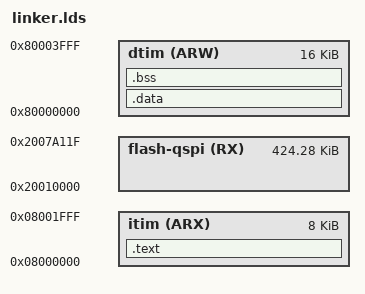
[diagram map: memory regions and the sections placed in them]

ENTRY(_start)

MEMORY
{
        itim       (ARX) : ORIGIN = 0x08000000, LENGTH = 8k
        flash-qspi (RX)  : ORIGIN = 0x20010000, LENGTH = 0x6A120
        dtim       (ARW) : ORIGIN = 0x80000000, LENGTH = 16k
}

SECTIONS
{
        /**********************************************************************
         *                                                                    *
         **********************************************************************/
        .text :
        {
                _stext = .;
                *(.startup)
                *(.text)
                *(.text.*)
                *(.rodata)
                *(.rodata.*)
                *(.srodata)
                *(.srodata.*)
                . = ALIGN(0x10);
                _etext = .;
        } > itim
        /**********************************************************************
         *                                                                    *
         **********************************************************************/
        .data :
        {
                _sdata = .;
                *(.data)
                *(.data.*)
                *(.sdata)
                *(.sdata.*)
                *(.sdata2)
                *(.sdata2.*)
                . = ALIGN(0x10);
                _edata = .;
        } > dtim
        /**********************************************************************
         *                                                                    *
         **********************************************************************/
        .bss ADDR(.data) + SIZEOF(.data) (NOLOAD) :
        {
                _sbss = .;
                *(.bss)
                *(.bss.*)
                *(.sbss)
                *(.sbss.*)
                *(COMMON)
                _ebss = .;
        } > dtim
        /**********************************************************************
         *                                                                    *
         **********************************************************************/
        .debug_info     0 : { *(.debug_info) }
        .debug_abbrev   0 : { *(.debug_abbrev) }
        .debug_aranges  0 : { *(.debug_aranges) }
        .debug_frame    0 : { *(.debug_frame) }
        .debug_line     0 : { *(.debug_line) }
        .debug_line_str 0 : { *(.debug_line_str) }
        .debug_loclists 0 : { *(.debug_loclists) }
        .debug_macro    0 : { *(.debug_macro) }
        .debug_names    0 : { *(.debug_names) }
        .debug_rnglists 0 : { *(.debug_rnglists) }
        .debug_str      0 : { *(.debug_str) }
        /**********************************************************************
         *                                                                    *
         **********************************************************************/
        /DISCARD/ :
        {
                *(*)
        }
}

